# STM32H533 register map
File version: 1.3
CPU: CM33 r0p0, little endian, MPU, FPU, 4 interrupt priority bits
Registers are 32-bit, read-write, reset 0x0 unless marked. A register's access mark holds for its fields unless they carry their own. Offsets are from the block's base; [hi:lo] are bit positions; {n}, {i} and the like mark numbered series; 'fields as' and 'values as' point back to an identical list.

## ICACHE — ICACHE register block
Base 0x40030400
Same registers: ICACHE_S 0x50030400
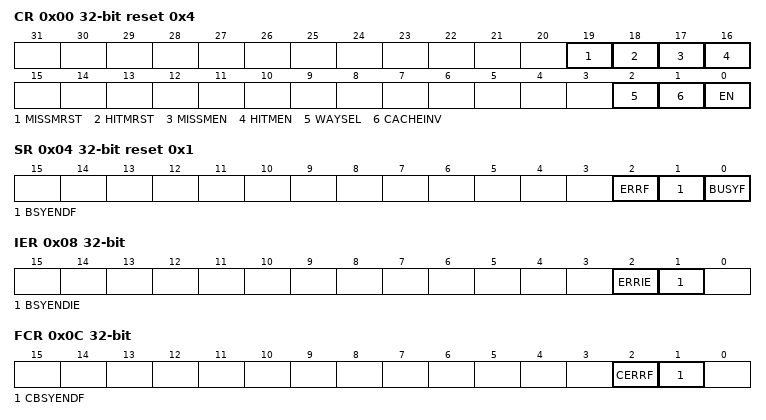
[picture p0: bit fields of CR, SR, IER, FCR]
0x00 CR reset 0x4 — ICACHE control register
  [19] MISSMRST — miss monitor reset
  [18] HITMRST — hit monitor reset
  [17] MISSMEN — miss monitor enable
  [16] HITMEN — hit monitor enable
  [2] WAYSEL — cache associativity mode selection
  [1] CACHEINV wo — cache invalidation
  [0] EN — enable
0x04 SR ro reset 0x1 — ICACHE status register
  [2] ERRF — cache error flag
  [1] BSYENDF — busy end flag
  [0] BUSYF — busy flag
0x08 IER — ICACHE interrupt enable register
  [2] ERRIE — interrupt enable on cache error
  [1] BSYENDIE — interrupt enable on busy end
0x0C FCR wo — ICACHE flag clear register
  [2] CERRF — clear cache error flag
  [1] CBSYENDF — clear busy end flag
0x10 HMONR ro — ICACHE hit monitor register
  [31:0] HITMON — cache hit monitor counter
0x14 MMONR ro — ICACHE miss monitor register
  [15:0] MISSMON — cache miss monitor counter
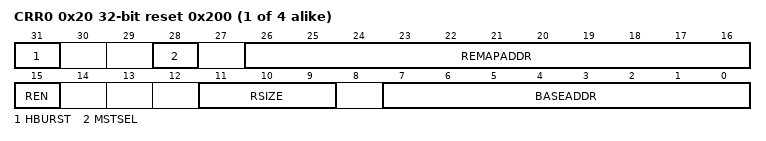
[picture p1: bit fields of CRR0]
{0x20+4i} CRR{i} reset 0x200 (i=0..3) — ICACHE region {i} configuration register
  [31] HBURST — output burst type for region x
  [28] MSTSEL — AHB cache master selection for region x
  [26:16] REMAPADDR — remapped address for region x
  [15] REN — enable for region x
  [11:9] RSIZE — size for region x
  [7:0] BASEADDR — base address for region x

## IWDG — IWDG address block description
Base 0x40003000
Same registers: IWDG_S 0x50003000
0x00 KR 16-bit wo — IWDG key register
  [15:0] KEY — Key value (write only, read 0x0000)
    0x5555=Unlock (Enable access to PR, RLR and WINR registers); 0xAAAA=Feed watchdog with RLR register value; 0xCCCC=Start the watchdog
0x04 PR 16-bit — IWDG prescaler register
  [3:0] PR — Prescaler divider
    0=DivideBy4 (Divider /4); 1=DivideBy8 (Divider /8); 2=DivideBy16 (Divider /16); 3=DivideBy32 (Divider /32); 4=DivideBy64 (Divider /64); 5=DivideBy128 (Divider /128); 6=DivideBy256 (Divider /256); 7=DivideBy512 (Divider /512); other=DivideBy1024 (Divider /1024)
0x08 RLR 16-bit reset 0xFFF — IWDG reload register
  [11:0] RL — Watchdog counter reload value
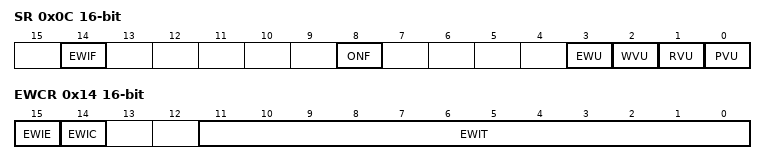
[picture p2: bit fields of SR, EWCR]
0x0C SR 16-bit ro — IWDG status register
  [14] EWIF — Watchdog early interrupt flag
    0=NotPending (No pending interrupt); 1=Pending (Interrupt pending)
  [8] ONF — Watchdog enable status bit
    0=NotActivated (IWDG is not activated); 1=Activated (IWDG is activated)
  [3] EWU — Watchdog interrupt comparator value update
    0=Idle (No update on-going); 1=Busy (Update on-going)
  [2] WVU — Watchdog counter window value update
    0=Idle (No update on-going); 1=Busy (Update on-going)
  [1] RVU — Watchdog counter reload value update
    0=Idle (No update on-going); 1=Busy (Update on-going)
  [0] PVU — Watchdog prescaler value update
    0=Idle (No update on-going); 1=Busy (Update on-going)
0x10 WINR 16-bit reset 0xFFF — IWDG window register
  [11:0] WIN — Watchdog counter window value
0x14 EWCR 16-bit — IWDG early wake-up interrupt register
  [15] EWIE — Watchdog early interrupt enable
  [14] EWIC wo — Watchdog early interrupt acknowledge
  [11:0] EWIT — Watchdog counter window value

## OTFDEC1 — OTFDEC register bank
Base 0x46005000
Same registers: OTFDEC1_S 0x56005000
0x00 CR — OTFDEC control register
  [0] ENC — Encryption mode bit
0x10 PRIVCFGR — OTFDEC privileged access control configuration register
  [0] PRIV — Privileged access protection.
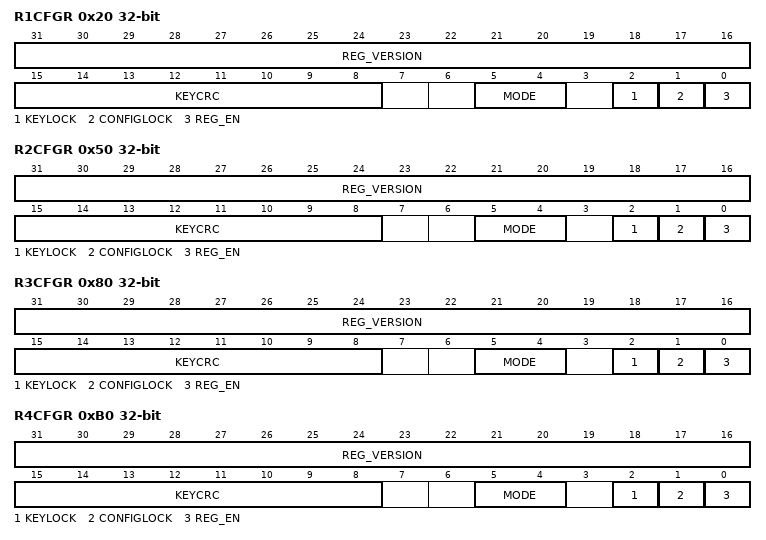
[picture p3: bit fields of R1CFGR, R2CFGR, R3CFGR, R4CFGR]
0x20 R1CFGR — OTFDEC region 1 configuration register
  [31:16] REG_VERSION — region firmware version
  [15:8] KEYCRC ro — region key 8-bit CRC
  [5:4] MODE — operating mode
  [2] KEYLOCK — region key lock
  [1] CONFIGLOCK — region config lock
  [0] REG_EN — region on-the-fly decryption enable
0x24 R1STARTADDR — OTFDEC region 1 start address register
  [31:0] REG_START_ADDR — Region AHB start address
0x28 R1ENDADDR reset 0xFFF — OTFDEC region 1 end address register
  [31:0] REG_END_ADDR — Region AHB end address
0x2C R1NONCER0 — OTFDEC region 1 nonce register 0
  [31:0] REG_NONCE — Region nonce, bits [31:0]
{0x0+0x30*i} R{i}NONCER1 (i=1..4) — OTFDEC region {i} nonce register 1
  [31:0] REG_NONCE — Region nonce, bits [63:32]
{0x4+0x30*i} R{i}KEYR0 wo (i=1..4) — OTFDEC region {i} key register 0
  [31:0] REG_KEY — Region key, bits [31:0]
{0x8+0x30*i} R{i}KEYR1 wo (i=1..4) — OTFDEC region {i} key register 1
  [31:0] REG_KEY — Region key, bits [63:32]
{0xC+0x30*i} R{i}KEYR2 wo (i=1..4) — OTFDEC region {i} key register 2
  [31:0] REG_KEY — Region key, bits [95:64]
{0x10+0x30*i} R{i}KEYR3 wo (i=1..4) — OTFDEC region {i} key register 3
  [31:0] REG_KEY — Region key, bits [127:96]
0x50 R2CFGR — OTFDEC region 2 configuration register
  fields as R1CFGR
0x54 R2STARTADDR — OTFDEC region 2 start address register
  [31:0] REG_START_ADDR — Region AHB start address
0x58 R2ENDADDR reset 0xFFF — OTFDEC region 2 end address register
  [31:0] REG_END_ADDR — Region AHB end address
0x5C R2NONCER0 — OTFDEC region 2 nonce register 0
  [31:0] REG_NONCE — Region nonce, bits [31:0]
0x80 R3CFGR — OTFDEC region 3 configuration register
  fields as R1CFGR
0x84 R3STARTADDR — OTFDEC region 3 start address register
  [31:0] REG_START_ADDR — Region AHB start address
0x88 R3ENDADDR reset 0xFFF — OTFDEC region 3 end address register
  [31:0] REG_END_ADDR — Region AHB end address
0x8C R3NONCER0 — OTFDEC region 3 nonce register 0
  [31:0] REG_NONCE — Region nonce, bits [31:0]
0xB0 R4CFGR — OTFDEC region 4 configuration register
  fields as R1CFGR
0xB4 R4STARTADDR — OTFDEC region 4 start address register
  [31:0] REG_START_ADDR — Region AHB start address
0xB8 R4ENDADDR reset 0xFFF — OTFDEC region 4 end address register
  [31:0] REG_END_ADDR — Region AHB end address
0xBC R4NONCER0 — OTFDEC region 4 nonce register 0
  [31:0] REG_NONCE — Region nonce, bits [31:0]
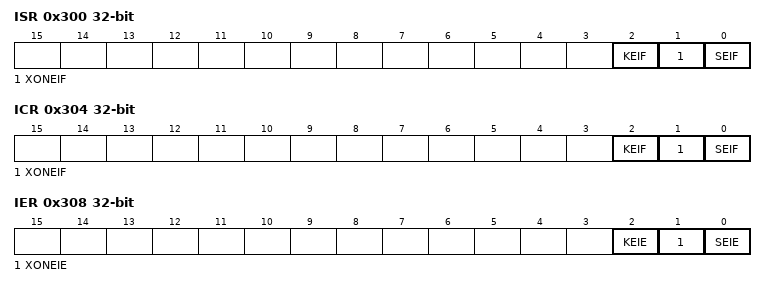
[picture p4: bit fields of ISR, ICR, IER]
0x300 ISR ro — OTFDEC interrupt status register
  [2] KEIF — Key error interrupt flag status
  [1] XONEIF — Execute-only execute-never error interrupt flag status
  [0] SEIF — Security error interrupt flag status
0x304 ICR wo — OTFDEC interrupt clear register
  [2] KEIF — Key error interrupt flag clear
  [1] XONEIF — Execute-only execute-never error interrupt flag clear
  [0] SEIF — Security error interrupt flag clear
0x308 IER — OTFDEC interrupt enable register
  [2] KEIE — Key error interrupt enable
  [1] XONEIE — Execute-only execute-never error interrupt enable
  [0] SEIE — Security error interrupt enable
